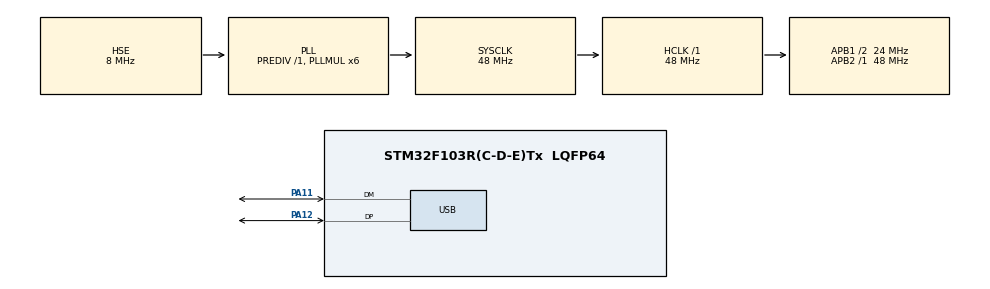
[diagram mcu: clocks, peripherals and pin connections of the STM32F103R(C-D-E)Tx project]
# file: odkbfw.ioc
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Mcu.Family=STM32F1
Mcu.Name=STM32F103R(C-D-E)Tx
Mcu.Package=LQFP64
NVIC.PriorityGroup=NVIC_PRIORITYGROUP_4
NVIC.USB_LP_CAN1_RX0_IRQn=true\:0\:0\:false\:false\:true\:false\:true
PA11.Mode=Device
PA11.Signal=USB_DM
PA12.Mode=Device
PA12.Signal=USB_DP
PA13.Mode=Serial_Wire
PA13.Signal=SYS_JTMS-SWDIO
PA14.Mode=Serial_Wire
PA14.Signal=SYS_JTCK-SWCLK
PD0-OSC_IN.Mode=HSE-External-Oscillator
PD0-OSC_IN.Signal=RCC_OSC_IN
PD1-OSC_OUT.Mode=HSE-External-Oscillator
PD1-OSC_OUT.Signal=RCC_OSC_OUT
ProjectManager.HeapSize=0x200
ProjectManager.StackSize=0x400
ProjectManager.TargetToolchain=STM32CubeIDE
RCC.AHBFreq_Value=48000000
RCC.APB1CLKDivider=RCC_HCLK_DIV2
RCC.APB1Freq_Value=24000000
RCC.APB1TimFreq_Value=48000000
RCC.APB2Freq_Value=48000000
RCC.APB2TimFreq_Value=48000000
RCC.HCLKFreq_Value=48000000
RCC.PLLMUL=RCC_PLL_MUL6
RCC.SYSCLKFreq_VALUE=48000000
RCC.SYSCLKSource=RCC_SYSCLKSOURCE_PLLCLK
RCC.USBFreq_Value=48000000
TIM1.Channel-PWM\ Generation4\ No\ Output=TIM_CHANNEL_4
USB_DEVICE.CLASS_NAME_FS=HID
USB_DEVICE.VirtualMode=Hid
USB_DEVICE.VirtualModeFS=Hid_FS
VP_TIM1_VS_no_output4.Mode=PWM Generation4 No Output
VP_USB_DEVICE_VS_USB_DEVICE_HID_FS.Mode=HID_FS
board=custom

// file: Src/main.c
/* USER CODE BEGIN Header */
/**
  ******************************************************************************
  * @file           : main.c
  * @brief          : Main program body
  ******************************************************************************
  * @attention
  *
  * <h2><center>&copy; Copyright (c) 2019 STMicroelectronics.
  * All rights reserved.</center></h2>
  *
  * This software component is licensed by ST under BSD 3-Clause license,
  * the "License"; You may not use this file except in compliance with the
  * License. You may obtain a copy of the License at:
  *                        opensource.org/licenses/BSD-3-Clause
  *
  ******************************************************************************
  */
/* USER CODE END Header */

#include "main.h"
#include "usb_device.h"

TIM_HandleTypeDef htim1;

void SystemClock_Config(void);
static void MX_GPIO_Init(void);
static void MX_TIM1_Init(void);

extern USBD_HandleTypeDef hUsbDeviceFS;
int main(void)
{
  /* USER CODE BEGIN 1 */
	uint8_t HIDbuffer[8] = {0};
	// modifiers in 0, zero in 1, char code in 2-7
	uint8_t *buf;
	uint32_t USBDelay;

  /* USER CODE END 1 */

  /* MCU Configuration--------------------------------------------------------*/

  /* Reset of all peripherals, Initializes the Flash interface and the Systick. */
  HAL_Init();

  /* Configure the system clock */
  SystemClock_Config();

  /* Initialize all configured peripherals */
  MX_GPIO_Init();
  MX_USB_DEVICE_Init();
  MX_TIM1_Init();
  /* USER CODE BEGIN 2 */

	buf = HIDbuffer;
	USBDelay = USBD_HID_GetPollingInterval(&hUsbDeviceFS);
	HIDbuffer[2] = 0x38;

  /* USER CODE END 2 */

  /* Infinite loop */
  while (1)
  {
	  HAL_Delay(1500);
	  HIDbuffer[2] = 0x38;
	  USBD_HID_SendReport(&hUsbDeviceFS, buf, 8);

	  HAL_Delay(150);
	  HIDbuffer[2] = 0x0;
	  USBD_HID_SendReport(&hUsbDeviceFS, buf, 8);

  }
}

void SystemClock_Config(void)
{
  RCC_OscInitTypeDef RCC_OscInitStruct = {0};
  RCC_ClkInitTypeDef RCC_ClkInitStruct = {0};
  RCC_PeriphCLKInitTypeDef PeriphClkInit = {0};

  /** Initializes the CPU, AHB and APB busses clocks
  */
  RCC_OscInitStruct.OscillatorType = RCC_OSCILLATORTYPE_HSE;
  RCC_OscInitStruct.HSEState = RCC_HSE_ON;
  RCC_OscInitStruct.HSEPredivValue = RCC_HSE_PREDIV_DIV1;
  RCC_OscInitStruct.HSIState = RCC_HSI_ON;
  RCC_OscInitStruct.PLL.PLLState = RCC_PLL_ON;
  RCC_OscInitStruct.PLL.PLLSource = RCC_PLLSOURCE_HSE;
  RCC_OscInitStruct.PLL.PLLMUL = RCC_PLL_MUL6;
  if (HAL_RCC_OscConfig(&RCC_OscInitStruct) != HAL_OK)
  {
    Error_Handler();
  }
  /** Initializes the CPU, AHB and APB busses clocks
  */
  RCC_ClkInitStruct.ClockType = RCC_CLOCKTYPE_HCLK|RCC_CLOCKTYPE_SYSCLK
                              |RCC_CLOCKTYPE_PCLK1|RCC_CLOCKTYPE_PCLK2;
  RCC_ClkInitStruct.SYSCLKSource = RCC_SYSCLKSOURCE_PLLCLK;
  RCC_ClkInitStruct.AHBCLKDivider = RCC_SYSCLK_DIV1;
  RCC_ClkInitStruct.APB1CLKDivider = RCC_HCLK_DIV2;
  RCC_ClkInitStruct.APB2CLKDivider = RCC_HCLK_DIV1;

  if (HAL_RCC_ClockConfig(&RCC_ClkInitStruct, FLASH_LATENCY_1) != HAL_OK)
  {
    Error_Handler();
  }
  PeriphClkInit.PeriphClockSelection = RCC_PERIPHCLK_USB;
  PeriphClkInit.UsbClockSelection = RCC_USBCLKSOURCE_PLL;
  if (HAL_RCCEx_PeriphCLKConfig(&PeriphClkInit) != HAL_OK)
  {
    Error_Handler();
  }
}

static void MX_TIM1_Init(void)
{

  TIM_MasterConfigTypeDef sMasterConfig = {0};
  TIM_OC_InitTypeDef sConfigOC = {0};
  TIM_BreakDeadTimeConfigTypeDef sBreakDeadTimeConfig = {0};

  htim1.Instance = TIM1;
  htim1.Init.Prescaler = 0;
  htim1.Init.CounterMode = TIM_COUNTERMODE_UP;
  htim1.Init.Period = 0;
  htim1.Init.ClockDivision = TIM_CLOCKDIVISION_DIV1;
  htim1.Init.RepetitionCounter = 0;
  htim1.Init.AutoReloadPreload = TIM_AUTORELOAD_PRELOAD_DISABLE;
  if (HAL_TIM_PWM_Init(&htim1) != HAL_OK)
  {
    Error_Handler();
  }
  sMasterConfig.MasterOutputTrigger = TIM_TRGO_RESET;
  sMasterConfig.MasterSlaveMode = TIM_MASTERSLAVEMODE_DISABLE;
  if (HAL_TIMEx_MasterConfigSynchronization(&htim1, &sMasterConfig) != HAL_OK)
  {
    Error_Handler();
  }
  sConfigOC.OCMode = TIM_OCMODE_PWM1;
  sConfigOC.Pulse = 0;
  sConfigOC.OCPolarity = TIM_OCPOLARITY_HIGH;
  sConfigOC.OCFastMode = TIM_OCFAST_DISABLE;
  sConfigOC.OCIdleState = TIM_OCIDLESTATE_RESET;
  sConfigOC.OCNIdleState = TIM_OCNIDLESTATE_RESET;
  if (HAL_TIM_PWM_ConfigChannel(&htim1, &sConfigOC, TIM_CHANNEL_4) != HAL_OK)
  {
    Error_Handler();
  }
  sBreakDeadTimeConfig.OffStateRunMode = TIM_OSSR_DISABLE;
  sBreakDeadTimeConfig.OffStateIDLEMode = TIM_OSSI_DISABLE;
  sBreakDeadTimeConfig.LockLevel = TIM_LOCKLEVEL_OFF;
  sBreakDeadTimeConfig.DeadTime = 0;
  sBreakDeadTimeConfig.BreakState = TIM_BREAK_DISABLE;
  sBreakDeadTimeConfig.BreakPolarity = TIM_BREAKPOLARITY_HIGH;
  sBreakDeadTimeConfig.AutomaticOutput = TIM_AUTOMATICOUTPUT_DISABLE;
  if (HAL_TIMEx_ConfigBreakDeadTime(&htim1, &sBreakDeadTimeConfig) != HAL_OK)
  {
    Error_Handler();
  }

}

static void MX_GPIO_Init(void)
{

  /* GPIO Ports Clock Enable */
  __HAL_RCC_GPIOD_CLK_ENABLE();
  __HAL_RCC_GPIOA_CLK_ENABLE();

}

void Error_Handler(void)
{
}

/************************ (C) COPYRIGHT STMicroelectronics *****END OF FILE****/
